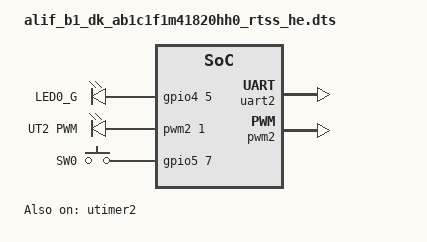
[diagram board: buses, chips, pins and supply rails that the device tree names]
/* Copyright (c) 2025 Alif Semiconductor
 *
 * SPDX-License-Identifier: Apache-2.0
 */

/dts-v1/;

#include <alif/balletto/b1/ab1c1f1m41820hh0.dtsi>
#include "../common/balletto-pinctrl.dtsi"

/ {
	compatible = "arm,alif-b1-dk-ab1c1f1m41820hh0-rtss-he";
	#address-cells = <1>;
	#size-cells = <1>;
};

&{/} {
	chosen {
		zephyr,console = &uart2;
		zephyr,shell-uart = &uart2;
	};

	aliases {
		led0 = &aled0;
		pwm-led0 = &pwm_ut2;
		sw0 = &button0;
		watchdog0 = &wdog0;
	};

	leds {
		compatible = "gpio-leds";
		aled0: led_0 {
			gpios = <&gpio4 5 0>;
			label = "LED0_G";
		};
	};

	pwmleds {
		compatible = "pwm-leds";
		pwm_ut2: pwm_ut2 {
			pwms = <&pwm2 1 PWM_MSEC(20) PWM_POLARITY_NORMAL>;
			label = "UT2 PWM";
		};
	};

	buttons {
		compatible = "gpio-keys";
		button0: button_0 {
			gpios = <&gpio5 7 0>;
			label = "SW0";
		};
	};
};

&uart2 {
	status = "okay";
};

&gpio4 {
	status = "okay";
};

&utimer2 {
	status = "okay";

	pwm2: pwm {
		pinctrl-0 = <&pinctrl_ut2>;
		pinctrl-names = "default";
		status = "okay";
	};
};
